VERSION ""

NS_ :

BS_:

BU_: TEST_NODE Pedalbox HUB_FL TORQUE_VECTOR TESTER IMU Precharge Precharge

BO_ 2483028044 test_msg: 2 TEST_NODE
 SG_ test_sig : 0|16@1+ (1,0) [0|0] "" Vector__XXX

BO_ 2483028619 throttle_brake: 4 Pedalbox
 SG_ raw_brake : 16|16@1+ (1,0) [0|0] "" Vector__XXX
 SG_ raw_throttle : 0|16@1+ (1,0) [0|0] "" Vector__XXX

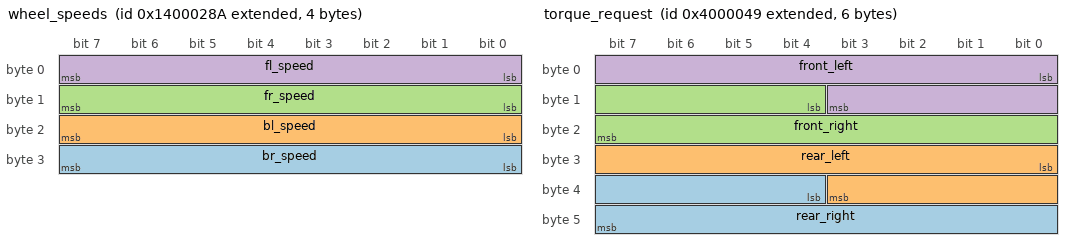
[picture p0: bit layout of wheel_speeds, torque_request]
BO_ 2483028618 wheel_speeds: 4 HUB_FL
 SG_ br_speed : 24|8@1+ (1,0) [0|0] "" Vector__XXX
 SG_ bl_speed : 16|8@1+ (1,0) [0|0] "" Vector__XXX
 SG_ fr_speed : 8|8@1+ (1,0) [0|0] "" Vector__XXX
 SG_ fl_speed : 0|8@1+ (1,0) [0|0] "" Vector__XXX

BO_ 2214592650 motor_current: 1 HUB_FL
 SG_ current : 0|8@1+ (1,0) [0|0] "" Vector__XXX

BO_ 2214592585 torque_request: 6 TORQUE_VECTOR
 SG_ rear_right : 36|12@1+ (1,0) [0|0] "" Vector__XXX
 SG_ rear_left : 24|12@1+ (1,0) [0|0] "" Vector__XXX
 SG_ front_right : 12|12@1+ (1,0) [0|0] "" Vector__XXX
 SG_ front_left : 0|12@1+ (1,0) [0|0] "" Vector__XXX

BO_ 2147490057 bitstream_flash_status: 1 TORQUE_VECTOR
 SG_ flash_timeout_rx : 1|1@1+ (1,0) [0|0] "" Vector__XXX
 SG_ flash_success : 0|1@1+ (1,0) [0|0] "" Vector__XXX

BO_ 2415925567 bitstream_data: 8 TESTER
 SG_ word_1 : 32|32@1+ (1,0) [0|0] "" Vector__XXX
 SG_ word_0 : 0|32@1+ (1,0) [0|0] "" Vector__XXX

BO_ 2415925631 bitstream_request: 5 TESTER
 SG_ download_size : 1|32@1+ (1,0) [0|0] "" Vector__XXX
 SG_ download_request : 0|1@1+ (1,0) [0|0] "" Vector__XXX

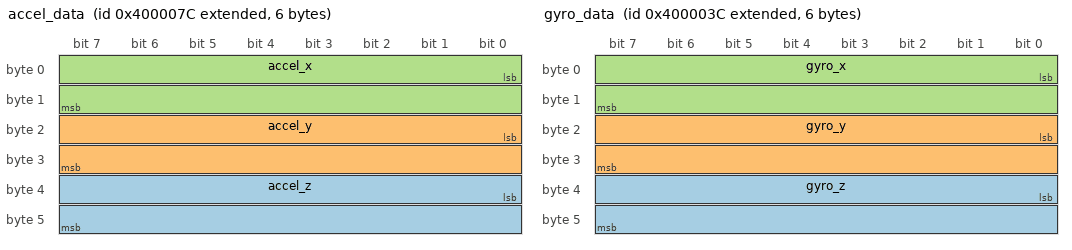
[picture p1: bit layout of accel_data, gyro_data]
BO_ 2214592636 accel_data: 6 IMU
 SG_ accel_z : 32|16@1+ (1,0) [0|0] "" Vector__XXX
 SG_ accel_y : 16|16@1+ (1,0) [0|0] "" Vector__XXX
 SG_ accel_x : 0|16@1+ (1,0) [0|0] "" Vector__XXX

BO_ 2214592572 gyro_data: 6 IMU
 SG_ gyro_z : 32|16@1+ (1,0) [0|0] "" Vector__XXX
 SG_ gyro_y : 16|16@1+ (1,0) [0|0] "" Vector__XXX
 SG_ gyro_x : 0|16@1+ (1,0) [0|0] "" Vector__XXX

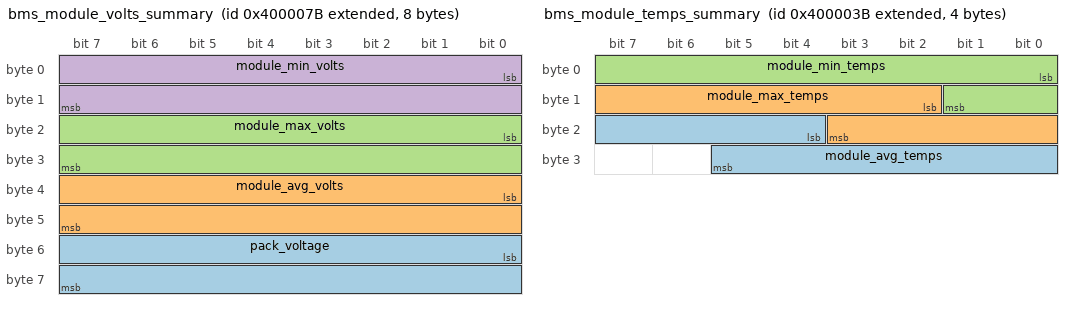
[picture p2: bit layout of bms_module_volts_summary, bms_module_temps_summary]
BO_ 2214592635 bms_module_volts_summary: 8 Precharge
 SG_ pack_voltage : 48|16@1+ (1,0) [0|0] "" Vector__XXX
 SG_ module_avg_volts : 32|16@1+ (1,0) [0|0] "" Vector__XXX
 SG_ module_max_volts : 16|16@1+ (1,0) [0|0] "" Vector__XXX
 SG_ module_min_volts : 0|16@1+ (1,0) [0|0] "" Vector__XXX

BO_ 2214592571 bms_module_temps_summary: 4 Precharge
 SG_ module_avg_temps : 20|10@1+ (1,0) [0|0] "" Vector__XXX
 SG_ module_max_temps : 10|10@1+ (1,0) [0|0] "" Vector__XXX
 SG_ module_min_temps : 0|10@1+ (1,0) [0|0] "" Vector__XXX

CM_ BO_ 2483028044 "test_msg desc";
CM_ BO_ 2483028619 "throttle_brake desc";
CM_ BO_ 2483028618 "wheel_speeds desc";
CM_ BO_ 2214592650 "current of motor";
CM_ BO_ 2214592585 "Torque request for all motors.";
CM_ BO_ 2147490057 "Status message for bitstream flashing";
CM_ BO_ 2415925567 "Bitstream download command";
CM_ BO_ 2415925631 "Bitstream state command";
CM_ BO_ 2214592636 "accelerometer data";
CM_ BO_ 2214592572 "gyroscope data";
CM_ BO_ 2214592635 "Summary of voltage data from bms modules";
CM_ BO_ 2214592571 "Summary of temperature data from bms modules";
